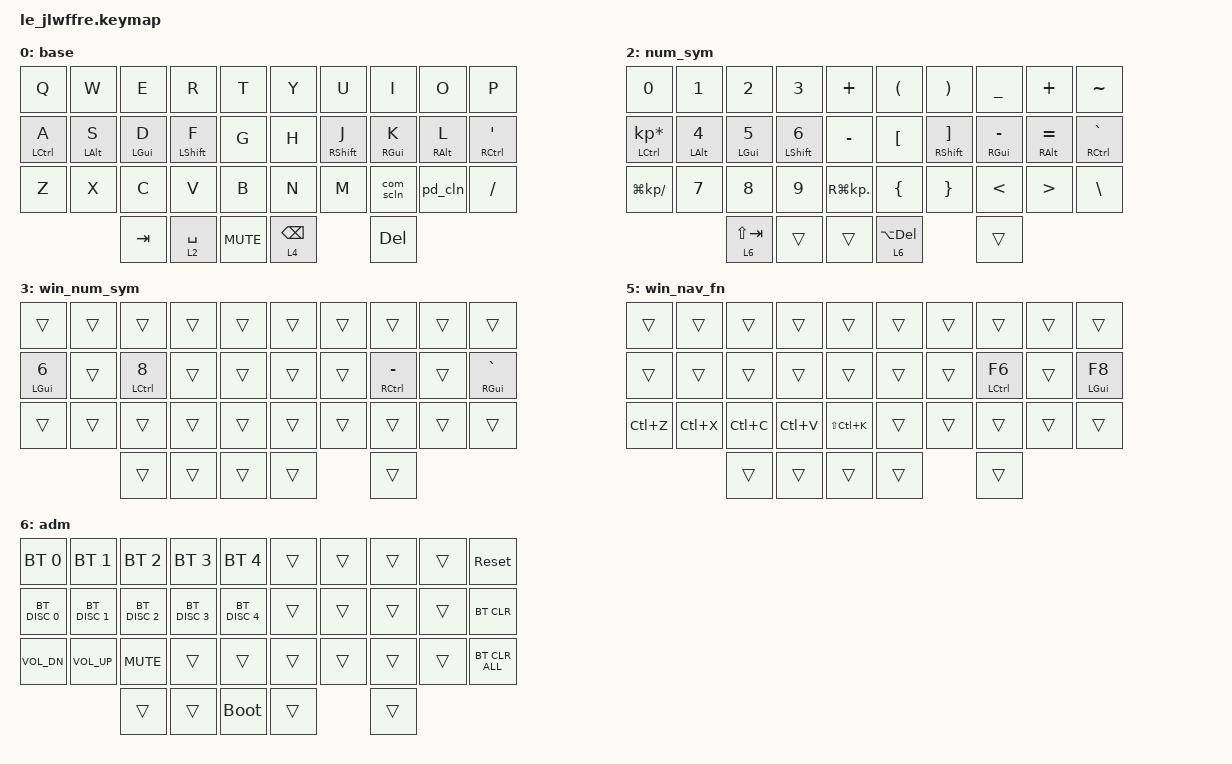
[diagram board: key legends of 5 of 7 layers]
/*
 * Copyright (c) 2022 The ZMK Contributors
 *
 * SPDX-License-Identifier: MIT
 */

#include <behaviors.dtsi>
#include <dt-bindings/zmk/bt.h>
#include <dt-bindings/zmk/keys.h>

/ {
    combos {
        compatible = "zmk,combos";

        left_enter {
            bindings = <&kp ENTER>;
            key-positions = <1 12 23>;
        };

        right_enter {
            bindings = <&kp ENTER>;
            key-positions = <8 17 26>;
        };

        esc {
            bindings = <&kp ESCAPE>;
            key-positions = <0 1>;
        };

        tab {
            bindings = <&kp TAB>;
            key-positions = <3 14>;
        };

        shift_tab {
            bindings = <&kp LS(TAB)>;
            key-positions = <2 13>;
        };

        hold_space {
            bindings = <&kp SPACE>;
            key-positions = <23 31>;
        };

        caps_word {
            bindings = <&caps_word>;
            key-positions = <13 16>;
        };

        toggle_nav {
            bindings = <&tog 2>;
            key-positions = <11 2 13>;
            layers = <0 2>;
            require-prior-idle-ms = <350>;
        };

        jsdoc {
            bindings = <&jsdoc>;
            key-positions = <29 28>;
        };

        caps_lock {
            bindings = <&kp CAPSLOCK>;
            key-positions = <13 12 16 17>;
        };

        screen_shot {
            bindings = <&kp LS(LG(N5))>;
            key-positions = <0 11>;
        };

        soft_off {
            bindings = <&soft_off>;
            key-positions = <0 9 31 33>;
        };

        bootloader {
            bindings = <&bootloader>;
            key-positions = <4 14 5 15>;
        };

        bt_clear_all {
            bindings = <&bt BT_CLR_ALL>;
            key-positions = <20 21 29 28 22 27>;
        };

        reset {
            bindings = <&sys_reset>;
            key-positions = <30 31 32 33 34 35>;
        };

        globe {
            bindings = <&kp GLOBE>;
            key-positions = <21 20 22>;
        };

        toggle_win {
            bindings = <&tog 1>;
            key-positions = <0 9>;
        };

        screenshot_win {
            bindings = <&kp LS(LG(S))>;
            key-positions = <0 11>;
            layers = <1>;
        };

        force_quit_mac {
            bindings = <&kp LA(LG(ESCAPE))>;
            key-positions = <0 1 2>;
        };

        mo_6_left {
            bindings = <&mo 6>;
            key-positions = <30 31>;
        };

        mo_6_right {
            bindings = <&mo 6>;
            key-positions = <33 34>;
        };

        studio_unlock {
            bindings = <&studio_unlock>;
            key-positions = <20 21 28 29>;
        };
    };

    behaviors {
        hml: HOMEROW_L_MODS {
            compatible = "zmk,behavior-hold-tap";
            label = "HOMEROW_L_MODS";
            bindings = <&kp>, <&kp>;

            #binding-cells = <2>;
            tapping-term-ms = <190>;
            quick-tap-ms = <190>;
            flavor = "balanced";
            require-prior-idle-ms = <100>;
            hold-trigger-key-positions = <5 6 7 8 9 15 16 17 18 19 25 26 27 28 33 34 29 13 12 11 10 32>;
        };

        hsl: HOMEROW_L_SHIFT {
            compatible = "zmk,behavior-hold-tap";
            label = "HOMEROW_L_SHIFT";
            bindings = <&kp>, <&kp>;

            #binding-cells = <2>;
            tapping-term-ms = <190>;
            quick-tap-ms = <190>;
            flavor = "balanced";
            require-prior-idle-ms = <0>;
            hold-trigger-key-positions = <5 15 25 6 16 26 7 8 9 9 17 18 19 27 28 34 33 29 32 13 12 11 10>;
        };

        com_scln: comma_semicolon {
            compatible = "zmk,behavior-mod-morph";
            label = "COMMA_SEMICOLON";
            bindings = <&kp COMMA>, <&kp SEMICOLON>;

            #binding-cells = <0>;
            mods = <(MOD_LSFT|MOD_RSFT)>;
        };

        pd_cln: period_colon {
            compatible = "zmk,behavior-mod-morph";
            label = "PERIOD_COLON";
            bindings = <&kp PERIOD>, <&kp COLON>;

            #binding-cells = <0>;
            mods = <(MOD_LSFT|MOD_RSFT)>;
        };

        hmr: HOMEROW_R_MODS {
            compatible = "zmk,behavior-hold-tap";
            label = "HOMEROW_R_MODS";
            bindings = <&kp>, <&kp>;

            #binding-cells = <2>;
            tapping-term-ms = <190>;
            quick-tap-ms = <190>;
            flavor = "balanced";
            require-prior-idle-ms = <100>;
            hold-trigger-key-positions = <0 1 2 3 4 10 11 12 13 14 20 21 22 23 24 32 31 16 17 18 19>;
        };

        hsr: HOMEROW_R_SHIFT {
            compatible = "zmk,behavior-hold-tap";
            label = "HOMEROW_R_SHIFT";
            bindings = <&kp>, <&kp>;

            #binding-cells = <2>;
            tapping-term-ms = <190>;
            quick-tap-ms = <190>;
            flavor = "balanced";
            require-prior-idle-ms = <0>;
            hold-trigger-key-positions = <0 1 2 3 4 10 11 12 13 14 20 21 22 23 24 31 32 16 17 18 19>;
        };

        bksp_del: bksp_del {
            compatible = "zmk,behavior-mod-morph";
            label = "BKSP_DEL";
            bindings = <&kp BACKSPACE>, <&kp DELETE>;

            #binding-cells = <0>;
            mods = <(MOD_LSFT)>;
        };
    };

    macros {
        jsdoc: jsdoc {
            compatible = "zmk,behavior-macro";
            #binding-cells = <0>;
            bindings = <&kp FSLH &kp STAR &kp STAR &kp SPACE>;
            label = "JSDOC";
        };
    };

    keymap {
        compatible = "zmk,keymap";

        base {
            bindings = <
&kp Q         &kp W        &kp E        &kp R         &kp T         &kp Y            &kp U         &kp I        &kp O        &kp P
&hml LCTRL A  &hml LALT S  &hml LGUI D  &hsl LSHFT F  &kp G         &kp H            &hsr RSHFT J  &hmr RGUI K  &hmr RALT L  &hmr RCTRL SQT
&kp Z         &kp X        &kp C        &kp V         &kp B         &kp N            &kp M         &com_scln    &pd_cln      &kp FSLH
                           &kp TAB      &lt 2 SPACE   &kp C_MUTE    &lt 4 BACKSPACE                &kp DELETE
            >;

            sensor-bindings = <&inc_dec_kp C_VOL_UP C_VOL_DN>;
        };

        win_base {
            bindings = <
&trans       &trans  &trans        &trans  &trans    &trans  &trans  &trans        &trans  &trans
&hml LGUI A  &trans  &hml LCTRL D  &trans  &trans    &trans  &trans  &hmr RCTRL K  &trans  &hmr RGUI SQT
&trans       &trans  &trans        &trans  &trans    &trans  &trans  &trans        &trans  &trans
                     &trans        &trans  &trans    &trans
            >;

            sensor-bindings = <&inc_dec_kp C_VOL_UP C_VOL_DN>;
        };

        num_sym {
            bindings = <
&kp N0                  &kp NUMBER_1            &kp NUMBER_2   &kp NUMBER_3        &kp PLUS          &kp LEFT_PARENTHESIS  &kp RIGHT_PARENTHESIS           &kp UNDER        &kp PLUS              &kp TILDE
&hml LCTRL KP_MULTIPLY  &hml LEFT_ALT NUMBER_4  &hml LGUI N5   &hsl LEFT_SHIFT N6  &kp MINUS         &kp LEFT_BRACKET      &hsr RIGHT_SHIFT RIGHT_BRACKET  &hmr RGUI MINUS  &hmr RIGHT_ALT EQUAL  &hmr RCTRL GRAVE
&kp LG(KP_DIVIDE)       &kp N7                  &kp N8         &kp N9              &kp RG(KP_DOT)    &kp LEFT_BRACE        &kp RIGHT_BRACE                 &kp LESS_THAN    &kp GREATER_THAN      &kp BSLH
                                                &lt 6 LS(TAB)  &trans              &trans            &lt 6 LA(DELETE)                                      &trans
            >;

            sensor-bindings = <&inc_dec_kp C_VOL_UP C_VOL_DN>;
        };

        win_num_sym {
            bindings = <
&trans              &trans  &trans         &trans  &trans    &trans  &trans  &trans            &trans  &trans
&hml LGUI NUMBER_6  &trans  &hml LCTRL N8  &trans  &trans    &trans  &trans  &hmr RCTRL MINUS  &trans  &hmr RGUI GRAVE
&trans              &trans  &trans         &trans  &trans    &trans  &trans  &trans            &trans  &trans
                            &trans         &trans  &trans    &trans          &trans
            >;

            sensor-bindings = <&inc_dec_kp C_VOL_UP C_VOL_DN>;
        };

        nav_fn {
            bindings = <
&mt LSHIFT PG_UP            &mt LEFT_ALT HOME  &mt LC(LSHIFT) UP_ARROW  &mt LEFT_ALT END     &kp LS(LA(LC(BACKSLASH)))    &trans  &kp F9         &kp F10       &kp F11            &kp F12
&mt LC(LEFT_CONTROL) PG_DN  &kp LEFT_ARROW     &kp DOWN_ARROW           &kp RIGHT_ARROW      &bksp_del                    &trans  &hsr RSHFT F5  &hmr RGUI F6  &hmr RIGHT_ALT F7  &hmr RCTRL F8
&kp LG(Z)                   &kp LG(X)          &kp LG(C)                &kp LG(V)            &kp LG(LS(K))                &trans  &kp F1         &kp F2        &kp F3             &kp F4
                                               &trans                   &lt 6 LA(BACKSPACE)  &trans                       &trans                 &trans
            >;

            sensor-bindings = <&inc_dec_kp C_VOL_UP C_VOL_DN>;
        };

        win_nav_fn {
            bindings = <
&trans     &trans     &trans     &trans     &trans           &trans  &trans  &trans         &trans  &trans
&trans     &trans     &trans     &trans     &trans           &trans  &trans  &hmr LCTRL F6  &trans  &hmr LGUI F8
&kp LC(Z)  &kp LC(X)  &kp LC(C)  &kp LC(V)  &kp LS(LC(K))    &trans  &trans  &trans         &trans  &trans
                      &trans     &trans     &trans           &trans          &trans
            >;

            sensor-bindings = <&inc_dec_kp C_VOL_UP C_VOL_DN>;
        };

        Admin {
            bindings = <
&bt BT_SEL 0   &bt BT_SEL 1   &bt BT_SEL 2   &bt BT_SEL 3   &bt BT_SEL 4     &trans  &trans  &trans  &trans  &sys_reset
&bt BT_DISC 0  &bt BT_DISC 1  &bt BT_DISC 2  &bt BT_DISC 3  &bt BT_DISC 4    &trans  &trans  &trans  &trans  &bt BT_CLR
&kp C_VOL_DN   &kp C_VOL_UP   &kp K_MUTE     &trans         &trans           &trans  &trans  &trans  &trans  &bt BT_CLR_ALL
                              &trans         &trans         &bootloader      &trans          &trans
            >;

            sensor-bindings = <&inc_dec_kp C_VOL_UP C_VOL_DN>;
            label = "adm";
        };
    };

    conditional_layers {
        compatible = "zmk,conditional-layers";

        num_sym_win {
            if-layers = <1 2>;
            then-layer = <3>;
        };

        nav_func_win {
            if-layers = <1 4>;
            then-layer = <5>;
        };
    };
};
